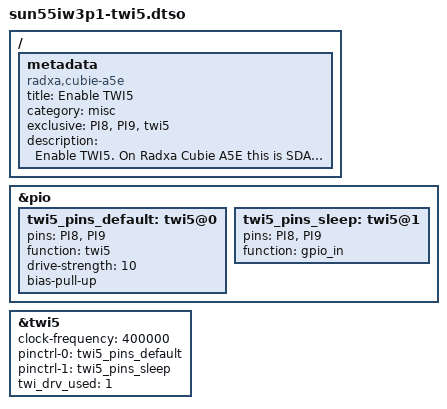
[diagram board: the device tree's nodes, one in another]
/dts-v1/;
/plugin/;

/ {
	metadata {
		title = "Enable TWI5";
		compatible = "radxa,cubie-a5e";
		category = "misc";
		exclusive = "PI8", "PI9", "twi5";
		description = "Enable TWI5.
On Radxa Cubie A5E this is SDA pin 11 & SCL pin 29.";
    };
};

&pio {
	twi5_pins_default: twi5@0 {
		pins = "PI8", "PI9";
		function = "twi5";
		drive-strength = <10>;
		bias-pull-up;
	};

	twi5_pins_sleep: twi5@1 {
		pins = "PI8", "PI9";
		function = "gpio_in";
	};
};

&twi5 {
	clock-frequency = <400000>;
	pinctrl-0 = <&twi5_pins_default>;
	pinctrl-1 = <&twi5_pins_sleep>;
	pinctrl-names = "default", "sleep";
	/* For stability and backwards compatibility, we recommend setting ‘twi_drv_used’ to 1 */
	twi_drv_used = <1>;
	status = "okay";
};
